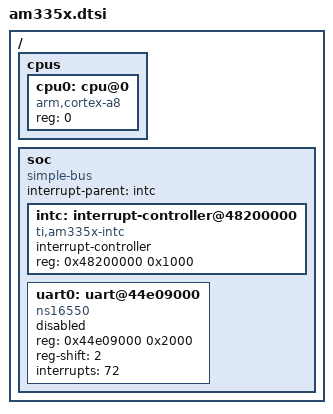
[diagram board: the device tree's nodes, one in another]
/*
 * Copyright (c) 2026 Manikanda Bharathi
 *
 * SPDX-License-Identifier: Apache-2.0
 */

#include <arm/armv7-a.dtsi>

/ {
	#address-cells = <1>;
	#size-cells = <1>;

	cpus {
		#address-cells = <1>;
		#size-cells = <0>;

		cpu0: cpu@0 {
			device_type = "cpu";
			compatible = "arm,cortex-a8";
			reg = <0>;
		};
	};

	soc {
		#address-cells = <1>;
		#size-cells = <1>;
		compatible = "simple-bus";
		interrupt-parent = <&intc>;
		ranges;

		intc: interrupt-controller@48200000 {
			compatible = "ti,am335x-intc";
			interrupt-controller;
			#interrupt-cells = <1>;
			reg = <0x48200000 0x1000>;
		};

		uart0: uart@44e09000 {
			compatible = "ns16550";
			reg = <0x44e09000 0x2000>;
			reg-shift = <2>;
			interrupts = <72>;
			status = "disabled";
		};
	};
};
